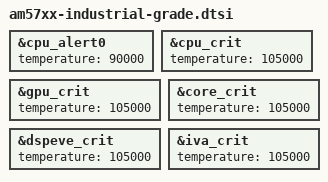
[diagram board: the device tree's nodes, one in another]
&cpu_alert0 {
	temperature = <90000>;  
};
&cpu_crit {
	temperature = <105000>;  
};
&gpu_crit {
	temperature = <105000>;  
};
&core_crit {
	temperature = <105000>;  
};
&dspeve_crit {
	temperature = <105000>;  
};
&iva_crit {
	temperature = <105000>;  
};
